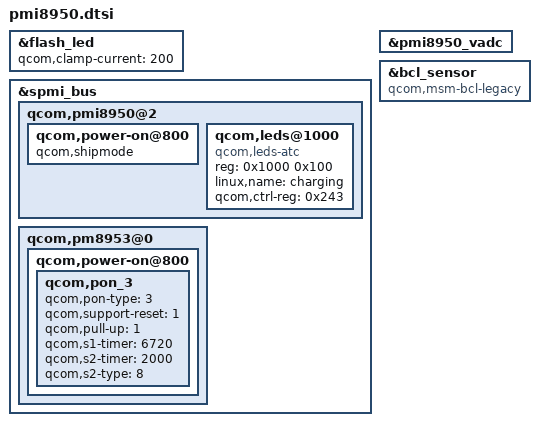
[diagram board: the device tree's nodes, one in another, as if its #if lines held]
&flash_led {
	/delete-property/ qcom,clamp-curr;
	qcom,clamp-current = <200>;
};

&spmi_bus {
	qcom,pmi8950@2 {
		qcom,power-on@800 {
			qcom,shipmode;
		};
	};
};

&pmi8950_vadc {
	/delete-node/ chan@d;
};

#ifdef CONFIG_MSM_BCL_PERIPHERAL_CTL_LEGACY
&bcl_sensor {
	compatible = "qcom,msm-bcl-legacy";
};
#endif

&spmi_bus {
	qcom,pmi8950@2 {
		/delete-node/ qcom,leds@a100;

		qcom,leds@1000 {
			status = "ok";
			reg = <0x1000 0x100>;
			compatible = "qcom,leds-atc";
			linux,name = "charging";
			qcom,ctrl-reg = <0x243>;
		};
	};

	qcom,pm8953@0 {
		qcom,power-on@800 {
			qcom,pon_3 {
				qcom,pon-type = <3>;
				qcom,support-reset = <1>;
				qcom,pull-up = <1>;
				qcom,s1-timer = <6720>;
				qcom,s2-timer = <2000>;
				qcom,s2-type = <8>;
			};
		};
	};
};
